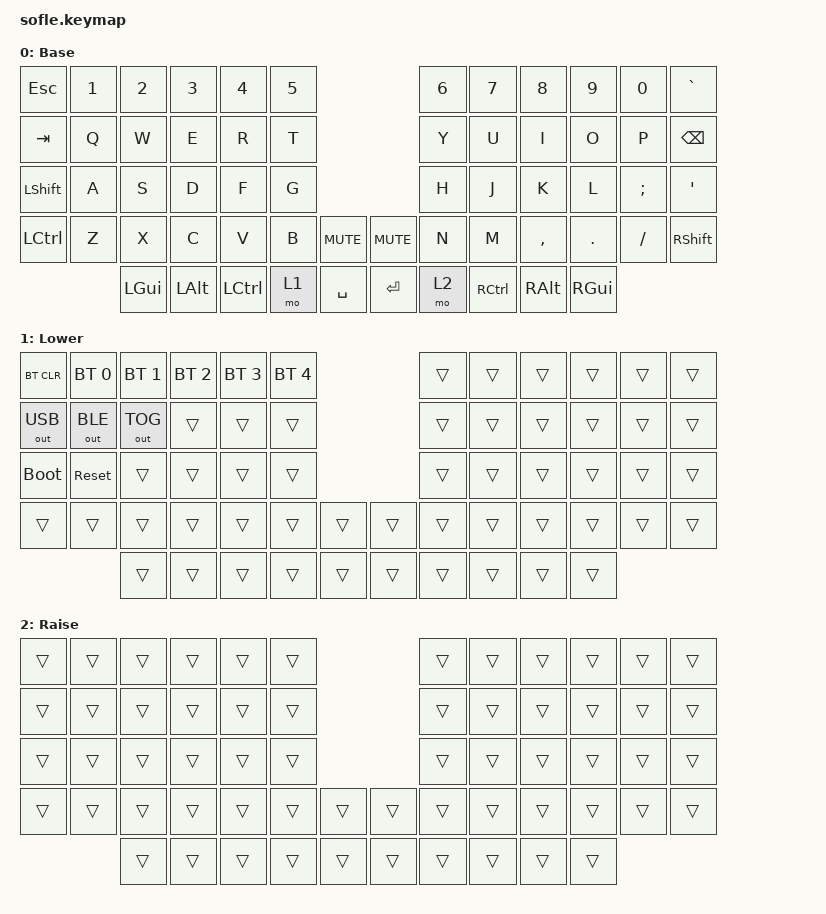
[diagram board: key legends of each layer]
#include <behaviors.dtsi>
#include <dt-bindings/zmk/keys.h>
#include <dt-bindings/zmk/bt.h>
#include <dt-bindings/zmk/outputs.h>

/ {
    keymap {
        compatible = "zmk,keymap";

        // Placeholder base layer. The binding COUNT (60) and the single
        // sensor-binding match the Sofle matrix, so this compiles as-is.
        // Re-map the keys however you like later.

        default_layer {
            display-name = "Base";
            bindings = <
&kp ESC   &kp N1 &kp N2   &kp N3   &kp N4    &kp N5                          &kp N6   &kp N7    &kp N8    &kp N9   &kp N0   &kp GRAVE
&kp TAB   &kp Q  &kp W    &kp E    &kp R     &kp T                           &kp Y    &kp U     &kp I     &kp O    &kp P    &kp BSPC
&kp LSHFT &kp A  &kp S    &kp D    &kp F     &kp G                           &kp H    &kp J     &kp K     &kp L    &kp SEMI &kp SQT
&kp LCTRL &kp Z  &kp X    &kp C    &kp V     &kp B   &kp C_MUTE   &kp C_MUTE  &kp N    &kp M     &kp COMMA &kp DOT  &kp FSLH &kp RSHFT
                 &kp LGUI &kp LALT &kp LCTRL &mo 1   &kp SPACE    &kp RET     &mo 2    &kp RCTRL &kp RALT  &kp RGUI
            >;

            sensor-bindings = <&inc_dec_kp C_VOLUME_UP C_VOLUME_DOWN>;

        };
lower_layer {
            display-name = "Lower";
            bindings = 
&bt BT_CLR   &bt BT_SEL 0 &bt BT_SEL 1 &bt BT_SEL 2 &bt BT_SEL 3 &bt BT_SEL 4                 &trans &trans &trans &trans &trans &trans
&out OUT_USB &out OUT_BLE &out OUT_TOG &trans       &trans       &trans                       &trans &trans &trans &trans &trans &trans
&bootloader  &sys_reset   &trans       &trans       &trans       &trans                       &trans &trans &trans &trans &trans &trans
&trans       &trans       &trans       &trans       &trans       &trans  &trans     &trans     &trans &trans &trans &trans &trans &trans
                          &trans       &trans       &trans       &trans  &trans     &trans     &trans &trans &trans &trans
            >;
            sensor-bindings = <&inc_dec_kp C_VOLUME_UP C_VOLUME_DOWN>;
        };

        raise_layer {
            display-name = "Raise";
            bindings = 
&trans &trans &trans &trans &trans &trans                 &trans &trans &trans &trans &trans &trans
&trans &trans &trans &trans &trans &trans                 &trans &trans &trans &trans &trans &trans
&trans &trans &trans &trans &trans &trans                 &trans &trans &trans &trans &trans &trans
&trans &trans &trans &trans &trans &trans &trans   &trans &trans &trans &trans &trans &trans &trans
              &trans &trans &trans &trans &trans   &trans &trans &trans &trans &trans
            >;
            sensor-bindings = <&inc_dec_kp C_VOLUME_UP C_VOLUME_DOWN>;
        };
    };
};
